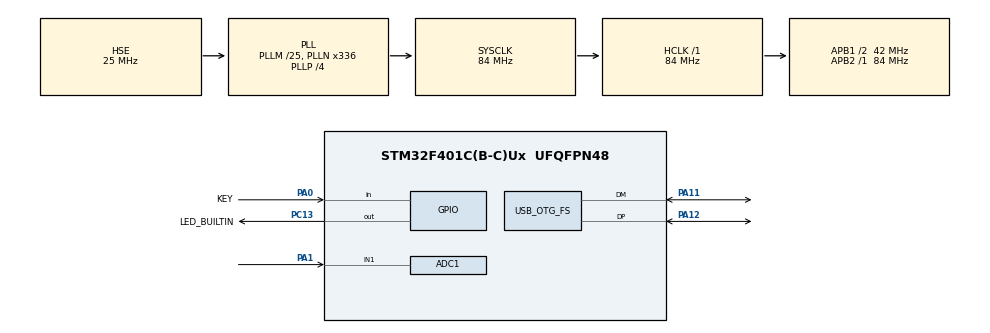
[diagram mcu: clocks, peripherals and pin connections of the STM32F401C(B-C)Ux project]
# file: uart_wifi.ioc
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ADC1.Channel-1\#ChannelRegularConversion=ADC_CHANNEL_1
ADC1.ContinuousConvMode=ENABLE
ADC1.NbrOfConversionFlag=1
ADC1.Rank-1\#ChannelRegularConversion=1
ADC1.Resolution=ADC_RESOLUTION_6B
ADC1.SamplingTime-1\#ChannelRegularConversion=ADC_SAMPLETIME_3CYCLES
ADC1.master=1
FREERTOS.INCLUDE_eTaskGetState=1
FREERTOS.INCLUDE_uxTaskGetStackHighWaterMark=1
FREERTOS.Queues01=BtnEvent,16,uint8_t,0,Static,BtnEventBuffer,BtnEventControlBlock
FREERTOS.Tasks01=defaultTask,24,128,StartDefaultTask,Default,NULL,Dynamic,NULL,NULL;ButtonPollTask,8,128,ButtonPoll,As external,NULL,Static,ButtonPollBuffer,ButtonPollControlBlock;BtnEventHandler,8,128,BtnEventHandler_task,As external,NULL,Static,BtnEventHandlerBuffer,BtnEventHandlerControlBlock
FREERTOS.configENABLE_FPU=1
FREERTOS.configUSE_NEWLIB_REENTRANT=1
Mcu.Family=STM32F4
Mcu.Name=STM32F401C(B-C)Ux
Mcu.Package=UFQFPN48
NVIC.OTG_FS_IRQn=true\:5\:0\:false\:false\:true\:true\:false\:true\:true
NVIC.PriorityGroup=NVIC_PRIORITYGROUP_4
NVIC.TIM1_UP_TIM10_IRQn=true\:15\:0\:false\:false\:true\:false\:false\:true\:true
NVIC.TimeBase=TIM1_UP_TIM10_IRQn
NVIC.TimeBaseIP=TIM1
PA0-WKUP.GPIO_Label=KEY
PA0-WKUP.GPIO_PuPd=GPIO_PULLUP
PA0-WKUP.Signal=GPIO_Input
PA1.Signal=ADCx_IN1
PA11.Mode=Device_Only
PA11.Signal=USB_OTG_FS_DM
PA12.Mode=Device_Only
PA12.Signal=USB_OTG_FS_DP
PC13-ANTI_TAMP.GPIO_Label=LED_BUILTIN
PC13-ANTI_TAMP.Signal=GPIO_Output
PC14-OSC32_IN.Mode=LSE-External-Oscillator
PC14-OSC32_IN.Signal=RCC_OSC32_IN
PC15-OSC32_OUT.Mode=LSE-External-Oscillator
PC15-OSC32_OUT.Signal=RCC_OSC32_OUT
PH0\ -\ OSC_IN.Mode=HSE-External-Oscillator
PH0\ -\ OSC_IN.Signal=RCC_OSC_IN
PH1\ -\ OSC_OUT.Mode=HSE-External-Oscillator
PH1\ -\ OSC_OUT.Signal=RCC_OSC_OUT
ProjectManager.HeapSize=0x200
ProjectManager.StackSize=0x400
ProjectManager.TargetToolchain=STM32CubeIDE
RCC.48MHZClocksFreq_Value=48000000
RCC.AHBFreq_Value=84000000
RCC.APB1CLKDivider=RCC_HCLK_DIV2
RCC.APB1Freq_Value=42000000
RCC.APB1TimFreq_Value=84000000
RCC.APB2Freq_Value=84000000
RCC.APB2TimFreq_Value=84000000
RCC.CortexFreq_Value=84000000
RCC.HCLKFreq_Value=84000000
RCC.HSE_VALUE=25000000
RCC.HSI_VALUE=16000000
RCC.PLLM=25
RCC.PLLN=336
RCC.PLLP=RCC_PLLP_DIV4
RCC.PLLQ=7
RCC.SYSCLKFreq_VALUE=84000000
RCC.SYSCLKSource=RCC_SYSCLKSOURCE_PLLCLK
RCC.VCOOutputFreq_Value=336000000
SH.ADCx_IN1.0=ADC1_IN1,IN1
USB_DEVICE.CLASS_NAME_FS=CDC
USB_DEVICE.VirtualMode=Cdc
USB_DEVICE.VirtualModeFS=Cdc_FS
USB_OTG_FS.VirtualMode=Device_Only
VP_CRC_VS_CRC.Mode=CRC_Activate
VP_FREERTOS_VS_CMSIS_V2.Mode=CMSIS_V2
VP_RTC_VS_RTC_Activate.Mode=RTC_Enabled
VP_RTC_VS_RTC_Calendar.Mode=RTC_Calendar
VP_SYS_VS_tim1.Mode=TIM1
VP_USB_DEVICE_VS_USB_DEVICE_CDC_FS.Mode=CDC_FS
board=custom

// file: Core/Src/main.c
/* USER CODE BEGIN Header */
/**
 ******************************************************************************
 * @file           : main.c
 * @brief          : Main program body
 ******************************************************************************
 * @attention
 *
 * Copyright (c) 2023 STMicroelectronics.
 * All rights reserved.
 *
 * This software is licensed under terms that can be found in the LICENSE file
 * in the root directory of this software component.
 * If no LICENSE file comes with this software, it is provided AS-IS.
 *
 ******************************************************************************
 */
/* USER CODE END Header */
#include "main.h"
#include "cmsis_os.h"
#include "usb_device.h"

typedef StaticTask_t osStaticThreadDef_t;
typedef StaticQueue_t osStaticMessageQDef_t;

ADC_HandleTypeDef hadc1;

CRC_HandleTypeDef hcrc;

RTC_HandleTypeDef hrtc;

/* Definitions for defaultTask */
osThreadId_t defaultTaskHandle;
const osThreadAttr_t defaultTask_attributes = {
  .name = "defaultTask",
  .stack_size = 128 * 4,
  .priority = (osPriority_t) osPriorityNormal,
};
/* Definitions for ButtonPollTask */
osThreadId_t ButtonPollTaskHandle;
uint32_t ButtonPollBuffer[ 128 ];
osStaticThreadDef_t ButtonPollControlBlock;
const osThreadAttr_t ButtonPollTask_attributes = {
  .name = "ButtonPollTask",
  .cb_mem = &ButtonPollControlBlock,
  .cb_size = sizeof(ButtonPollControlBlock),
  .stack_mem = &ButtonPollBuffer[0],
  .stack_size = sizeof(ButtonPollBuffer),
  .priority = (osPriority_t) osPriorityLow,
};
/* Definitions for BtnEventHandler */
osThreadId_t BtnEventHandlerHandle;
uint32_t BtnEventHandlerBuffer[ 128 ];
osStaticThreadDef_t BtnEventHandlerControlBlock;
const osThreadAttr_t BtnEventHandler_attributes = {
  .name = "BtnEventHandler",
  .cb_mem = &BtnEventHandlerControlBlock,
  .cb_size = sizeof(BtnEventHandlerControlBlock),
  .stack_mem = &BtnEventHandlerBuffer[0],
  .stack_size = sizeof(BtnEventHandlerBuffer),
  .priority = (osPriority_t) osPriorityLow,
};
/* Definitions for BtnEvent */
osMessageQueueId_t BtnEventHandle;
uint8_t BtnEventBuffer[ 16 * sizeof( uint8_t ) ];
osStaticMessageQDef_t BtnEventControlBlock;
const osMessageQueueAttr_t BtnEvent_attributes = {
  .name = "BtnEvent",
  .cb_mem = &BtnEventControlBlock,
  .cb_size = sizeof(BtnEventControlBlock),
  .mq_mem = &BtnEventBuffer,
  .mq_size = sizeof(BtnEventBuffer)
};

void SystemClock_Config(void);
static void MX_GPIO_Init(void);
static void MX_ADC1_Init(void);
static void MX_CRC_Init(void);
static void MX_RTC_Init(void);
void StartDefaultTask(void *argument);
extern void ButtonPoll(void *argument);
extern void BtnEventHandler_task(void *argument);

int main(void)
{

  /* MCU Configuration--------------------------------------------------------*/

  /* Reset of all peripherals, Initializes the Flash interface and the Systick. */
  HAL_Init();

  /* Configure the system clock */
  SystemClock_Config();

  /* Initialize all configured peripherals */
  MX_GPIO_Init();
  MX_ADC1_Init();
  MX_CRC_Init();
  MX_RTC_Init();

  /* Init scheduler */
  osKernelInitialize();

  /* Create the queue(s) */
  /* creation of BtnEvent */
  BtnEventHandle = osMessageQueueNew (16, sizeof(uint8_t), &BtnEvent_attributes);

  /* Create the thread(s) */
  /* creation of defaultTask */
  defaultTaskHandle = osThreadNew(StartDefaultTask, NULL, &defaultTask_attributes);

  /* creation of ButtonPollTask */
  ButtonPollTaskHandle = osThreadNew(ButtonPoll, NULL, &ButtonPollTask_attributes);

  /* creation of BtnEventHandler */
  BtnEventHandlerHandle = osThreadNew(BtnEventHandler_task, NULL, &BtnEventHandler_attributes);

  /* Start scheduler */
  osKernelStart();

  /* We should never get here as control is now taken by the scheduler */
  /* Infinite loop */
	while (1) {

	}
}

void SystemClock_Config(void)
{
  RCC_OscInitTypeDef RCC_OscInitStruct = {0};
  RCC_ClkInitTypeDef RCC_ClkInitStruct = {0};

  /** Configure the main internal regulator output voltage
  */
  __HAL_RCC_PWR_CLK_ENABLE();
  __HAL_PWR_VOLTAGESCALING_CONFIG(PWR_REGULATOR_VOLTAGE_SCALE2);

  /** Initializes the RCC Oscillators according to the specified parameters
  * in the RCC_OscInitTypeDef structure.
  */
  RCC_OscInitStruct.OscillatorType = RCC_OSCILLATORTYPE_LSI|RCC_OSCILLATORTYPE_HSE;
  RCC_OscInitStruct.HSEState = RCC_HSE_ON;
  RCC_OscInitStruct.LSIState = RCC_LSI_ON;
  RCC_OscInitStruct.PLL.PLLState = RCC_PLL_ON;
  RCC_OscInitStruct.PLL.PLLSource = RCC_PLLSOURCE_HSE;
  RCC_OscInitStruct.PLL.PLLM = 25;
  RCC_OscInitStruct.PLL.PLLN = 336;
  RCC_OscInitStruct.PLL.PLLP = RCC_PLLP_DIV4;
  RCC_OscInitStruct.PLL.PLLQ = 7;
  if (HAL_RCC_OscConfig(&RCC_OscInitStruct) != HAL_OK)
  {
    Error_Handler();
  }

  /** Initializes the CPU, AHB and APB buses clocks
  */
  RCC_ClkInitStruct.ClockType = RCC_CLOCKTYPE_HCLK|RCC_CLOCKTYPE_SYSCLK
                              |RCC_CLOCKTYPE_PCLK1|RCC_CLOCKTYPE_PCLK2;
  RCC_ClkInitStruct.SYSCLKSource = RCC_SYSCLKSOURCE_PLLCLK;
  RCC_ClkInitStruct.AHBCLKDivider = RCC_SYSCLK_DIV1;
  RCC_ClkInitStruct.APB1CLKDivider = RCC_HCLK_DIV2;
  RCC_ClkInitStruct.APB2CLKDivider = RCC_HCLK_DIV1;

  if (HAL_RCC_ClockConfig(&RCC_ClkInitStruct, FLASH_LATENCY_2) != HAL_OK)
  {
    Error_Handler();
  }
}

static void MX_ADC1_Init(void)
{

  ADC_ChannelConfTypeDef sConfig = {0};

  /** Configure the global features of the ADC (Clock, Resolution, Data Alignment and number of conversion)
  */
  hadc1.Instance = ADC1;
  hadc1.Init.ClockPrescaler = ADC_CLOCK_SYNC_PCLK_DIV4;
  hadc1.Init.Resolution = ADC_RESOLUTION_6B;
  hadc1.Init.ScanConvMode = DISABLE;
  hadc1.Init.ContinuousConvMode = ENABLE;
  hadc1.Init.DiscontinuousConvMode = DISABLE;
  hadc1.Init.ExternalTrigConvEdge = ADC_EXTERNALTRIGCONVEDGE_NONE;
  hadc1.Init.ExternalTrigConv = ADC_SOFTWARE_START;
  hadc1.Init.DataAlign = ADC_DATAALIGN_RIGHT;
  hadc1.Init.NbrOfConversion = 1;
  hadc1.Init.DMAContinuousRequests = DISABLE;
  hadc1.Init.EOCSelection = ADC_EOC_SINGLE_CONV;
  if (HAL_ADC_Init(&hadc1) != HAL_OK)
  {
    Error_Handler();
  }

  /** Configure for the selected ADC regular channel its corresponding rank in the sequencer and its sample time.
  */
  sConfig.Channel = ADC_CHANNEL_1;
  sConfig.Rank = 1;
  sConfig.SamplingTime = ADC_SAMPLETIME_3CYCLES;
  if (HAL_ADC_ConfigChannel(&hadc1, &sConfig) != HAL_OK)
  {
    Error_Handler();
  }

}

static void MX_CRC_Init(void)
{

  hcrc.Instance = CRC;
  if (HAL_CRC_Init(&hcrc) != HAL_OK)
  {
    Error_Handler();
  }

}

static void MX_RTC_Init(void)
{

  RTC_TimeTypeDef sTime = {0};
  RTC_DateTypeDef sDate = {0};

  /** Initialize RTC Only
  */
  hrtc.Instance = RTC;
  hrtc.Init.HourFormat = RTC_HOURFORMAT_24;
  hrtc.Init.AsynchPrediv = 127;
  hrtc.Init.SynchPrediv = 255;
  hrtc.Init.OutPut = RTC_OUTPUT_DISABLE;
  hrtc.Init.OutPutPolarity = RTC_OUTPUT_POLARITY_HIGH;
  hrtc.Init.OutPutType = RTC_OUTPUT_TYPE_OPENDRAIN;
  if (HAL_RTC_Init(&hrtc) != HAL_OK)
  {
    Error_Handler();
  }

  /** Initialize RTC and set the Time and Date
  */
  sTime.Hours = 0x0;
  sTime.Minutes = 0x0;
  sTime.Seconds = 0x0;
  sTime.DayLightSaving = RTC_DAYLIGHTSAVING_NONE;
  sTime.StoreOperation = RTC_STOREOPERATION_RESET;
  if (HAL_RTC_SetTime(&hrtc, &sTime, RTC_FORMAT_BCD) != HAL_OK)
  {
    Error_Handler();
  }
  sDate.WeekDay = RTC_WEEKDAY_MONDAY;
  sDate.Month = RTC_MONTH_JANUARY;
  sDate.Date = 0x1;
  sDate.Year = 0x0;

  if (HAL_RTC_SetDate(&hrtc, &sDate, RTC_FORMAT_BCD) != HAL_OK)
  {
    Error_Handler();
  }

}

static void MX_GPIO_Init(void)
{
  GPIO_InitTypeDef GPIO_InitStruct = {0};

  /* GPIO Ports Clock Enable */
  __HAL_RCC_GPIOC_CLK_ENABLE();
  __HAL_RCC_GPIOH_CLK_ENABLE();
  __HAL_RCC_GPIOA_CLK_ENABLE();

  /*Configure GPIO pin Output Level */
  HAL_GPIO_WritePin(LED_BUILTIN_GPIO_Port, LED_BUILTIN_Pin, GPIO_PIN_RESET);

  /*Configure GPIO pin : LED_BUILTIN_Pin */
  GPIO_InitStruct.Pin = LED_BUILTIN_Pin;
  GPIO_InitStruct.Mode = GPIO_MODE_OUTPUT_PP;
  GPIO_InitStruct.Pull = GPIO_NOPULL;
  GPIO_InitStruct.Speed = GPIO_SPEED_FREQ_LOW;
  HAL_GPIO_Init(LED_BUILTIN_GPIO_Port, &GPIO_InitStruct);

  /*Configure GPIO pin : KEY_Pin */
  GPIO_InitStruct.Pin = KEY_Pin;
  GPIO_InitStruct.Mode = GPIO_MODE_INPUT;
  GPIO_InitStruct.Pull = GPIO_PULLUP;
  HAL_GPIO_Init(KEY_GPIO_Port, &GPIO_InitStruct);

}

/* USER CODE BEGIN 4 */
void HAL_ADC_ConvCpltCallback(ADC_HandleTypeDef* hadc){
	printf("ADC VAL = %lu\n",HAL_ADC_GetValue(hadc));
}
void HAL_ADC_ErrorCallback(ADC_HandleTypeDef *hadc){
	printf("adc error\n");
}

/* USER CODE END 4 */

void StartDefaultTask(void *argument)
{
  /* init code for USB_DEVICE */
  MX_USB_DEVICE_Init();
  /* USER CODE BEGIN 5 */
  SEGGER_RTT_Init();
	HAL_GPIO_WritePin(LED_BUILTIN_GPIO_Port, LED_BUILTIN_Pin, GPIO_PIN_RESET);
	HAL_ADC_Start_IT(&hadc1);
	printf("Main start\n");
	/* Infinite loop */
	for (;;) {
		for (int x = 0; x < 4; x++) {
			HAL_GPIO_TogglePin(LED_BUILTIN_GPIO_Port, LED_BUILTIN_Pin);
			osDelay(250);
		}
	}
  /* USER CODE END 5 */
}

void HAL_TIM_PeriodElapsedCallback(TIM_HandleTypeDef *htim)
{
  if (htim->Instance == TIM1) {
    HAL_IncTick();
  }
}

void Error_Handler(void)
{
	__disable_irq();
	while (1) {
	}
}

#ifdef  USE_FULL_ASSERT
/**
  * @brief  Reports the name of the source file and the source line number
  *         where the assert_param error has occurred.
  * @param  file: pointer to the source file name
  * @param  line: assert_param error line source number
  * @retval None
  */
void assert_failed(uint8_t *file, uint32_t line)
{
  /* USER CODE BEGIN 6 */
	/* User can add his own implementation to report the file name and line number,
	 ex: printf("Wrong parameters value: file %s on line %d\r\n", file, line) */
	printf("ASSERT: file %s on line %lu\r\n", file, line);

  /* USER CODE END 6 */
}
#endif /* USE_FULL_ASSERT */
